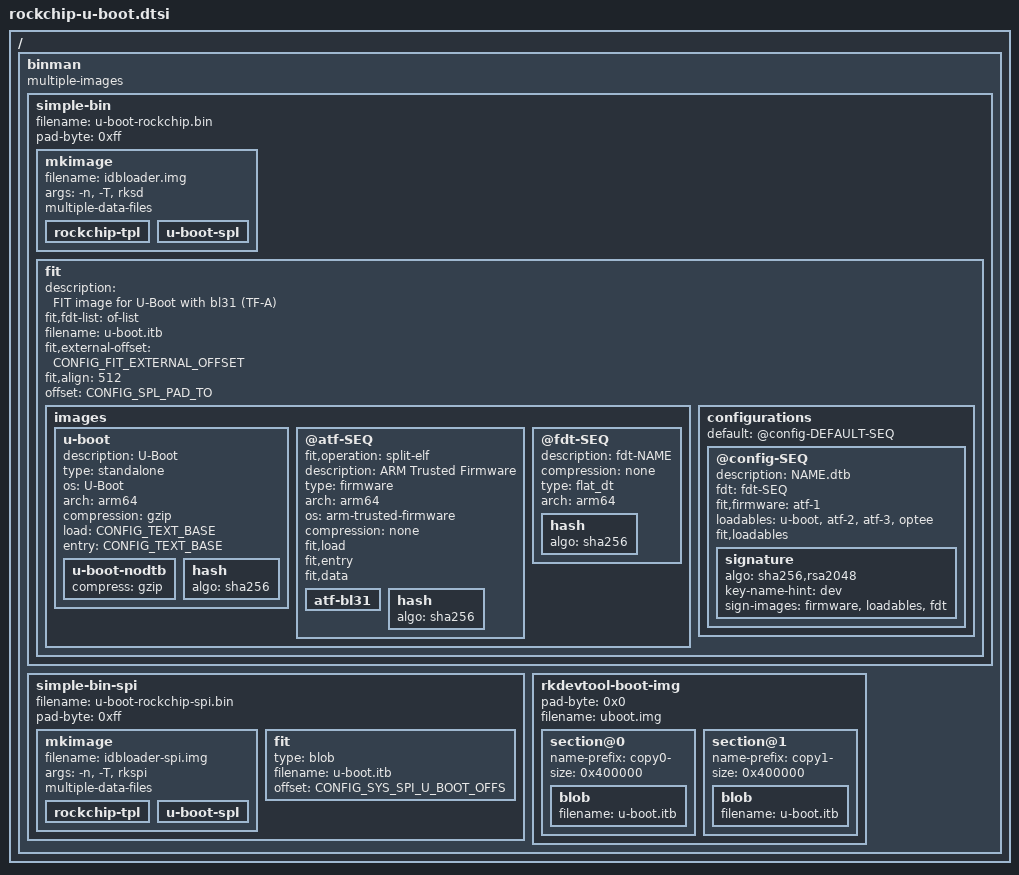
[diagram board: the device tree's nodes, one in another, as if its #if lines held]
// SPDX-License-Identifier: GPL-2.0+
/*
 * Copyright (C) 2019 Jagan Teki <jagan@amarulasolutions.com>
 */

#include <config.h>

/ {
    binman: binman {
        multiple-images;
    };
};

#ifdef CONFIG_SPL
&binman {
    simple-bin {
        filename = "u-boot-rockchip.bin";
        pad-byte = <0xff>;

        mkimage {
            filename = "idbloader.img";
            args = "-n", CONFIG_SYS_SOC, "-T", "rksd";
            multiple-data-files;

#ifdef CONFIG_ROCKCHIP_EXTERNAL_TPL
            rockchip-tpl {
            };
#elif defined(CONFIG_TPL)
            u-boot-tpl {
            };
#endif
            u-boot-spl {
            };
        };

#if defined(CONFIG_SPL_FIT) && (defined(CONFIG_ARM64) || defined(CONFIG_SPL_OPTEE_IMAGE))
        fit: fit {
#ifdef CONFIG_ARM64
            description = "FIT image for U-Boot with bl31 (TF-A)";
#else
            description = "FIT image with OP-TEE";
#endif
            #address-cells = <1>;
            fit,fdt-list = "of-list";
            filename = "u-boot.itb";
            fit,external-offset = <CONFIG_FIT_EXTERNAL_OFFSET>;
            fit,align = <512>;
            offset = <CONFIG_SPL_PAD_TO>;
            images {
                u-boot {
                    description = "U-Boot";
                    type = "standalone";
                    os = "U-Boot";
#ifdef CONFIG_ARM64
                    arch = "arm64";
#else
                    arch = "arm";
#endif
#if defined(CONFIG_SPL_GZIP)
                    compression = "gzip";
#elif defined(CONFIG_SPL_LZMA)
                    compression = "lzma";
#else
                    compression = "none";
#endif
                    load = <CONFIG_TEXT_BASE>;
                    entry = <CONFIG_TEXT_BASE>;
                    u-boot-nodtb {
#if defined(CONFIG_SPL_GZIP)
                    compress = "gzip";
#elif defined(CONFIG_SPL_LZMA)
                    compress = "lzma";
#endif
                    };
#ifdef CONFIG_SPL_FIT_SIGNATURE
                    hash {
                        algo = "sha256";
                    };
#endif
                };

#ifdef CONFIG_ARM64
                @atf-SEQ {
                    fit,operation = "split-elf";
                    description = "ARM Trusted Firmware";
                    type = "firmware";
                    arch = "arm64";
                    os = "arm-trusted-firmware";
                    compression = "none";
                    fit,load;
                    fit,entry;
                    fit,data;

                    atf-bl31 {
                    };
#ifdef CONFIG_SPL_FIT_SIGNATURE
                    hash {
                        algo = "sha256";
                    };
#endif
                };
#endif
//                optee {
//                    description = "OP-TEE";
//                    data = /incbin/("../../../tee.bin");
//                    type = "firmware";
//                    arch = "arm64";
//                    os = "tee";
//                    compression = "none";
//
//                    load = <0x8400000>;
//                    entry = <0x8400000>;
//#ifdef CONFIG_SPL_FIT_SIGNATURE
//                    hash {
//                        algo = "sha256";
//                    };
//#endif
//                };

                @fdt-SEQ {
                    description = "fdt-NAME";
                    compression = "none";
                    type = "flat_dt";
					arch = "arm64";
#ifdef CONFIG_SPL_FIT_SIGNATURE
                    hash {
                        algo = "sha256";
                    };
#endif
                };
            };

            configurations {
                default = "@config-DEFAULT-SEQ";
                @config-SEQ {
                    description = "NAME.dtb";
                    fdt = "fdt-SEQ";
#ifdef CONFIG_ARM64
                    fit,firmware = "atf-1";
                    loadables = "u-boot", "atf-2", "atf-3", "optee";

#else
                    fit,firmware = "op-tee", "u-boot";
#endif
                    fit,loadables;
                        signature {
                            algo = "sha256,rsa2048";
                            key-name-hint = "dev";
                            sign-images = "firmware", "loadables", "fdt";
                        };
                };
            };
        };
#else
        u-boot-img {
            offset = <CONFIG_SPL_PAD_TO>;
        };
#endif
    };

#ifdef CONFIG_ROCKCHIP_SPI_IMAGE
    simple-bin-spi {
        filename = "u-boot-rockchip-spi.bin";
        pad-byte = <0xff>;

        mkimage {
            filename = "idbloader-spi.img";
            args = "-n", CONFIG_SYS_SOC, "-T", "rkspi";
            multiple-data-files;

#ifdef CONFIG_ROCKCHIP_EXTERNAL_TPL
            rockchip-tpl {
            };
#elif defined(CONFIG_TPL)
            u-boot-tpl {
            };
#endif
            u-boot-spl {
            };
        };

#if defined(CONFIG_ARM64) || defined(CONFIG_SPL_OPTEE_IMAGE)
        fit {
            type = "blob";
            filename = "u-boot.itb";
#else
        u-boot-img {
#endif
#if defined(CONFIG_SYS_SPI_U_BOOT_OFFS)
            /* Sync with u-boot,spl-payload-offset if present */
            offset = <CONFIG_SYS_SPI_U_BOOT_OFFS>;
#endif
        };
    };
#endif /* CONFIG_ROCKCHIP_SPI_IMAGE */

        // This creates the "uboot" image part of a full Rockchip Firmware Upgrade package
        // (e.g. for recovering when the eMMC has been completely overwritten/corrupted).
        // This is typically written to partition 1, which starts at sector 0x4000 of the MMC
        // in the case of the RK3588. Other models may differ in partition number and sector offset.
        //
        // It appears that partition is internally split into two equal parts (2x 4MiB),
        // possibly to support Android A/B firmware updates (reserve / safety part).
        // For this reason, the image is written two times, bringing the final
        // length of uboot.img to 8 MiB. Note that this image will NOT contain the SPL or TPL.
        rkdevtool-boot-img {
                pad-byte = <0x0>;
                filename = "uboot.img";

                section@0 {
                        name-prefix = "copy0-";
                                size = <0x400000>;
                            blob {
                                    filename = "u-boot.itb";
                            };
                        };

                section@1 {
                        name-prefix = "copy1-";
                                size = <0x400000>;
                            blob {
                                    filename = "u-boot.itb";
                            };
                    };
                };

};
#endif /* CONFIG_SPL */
